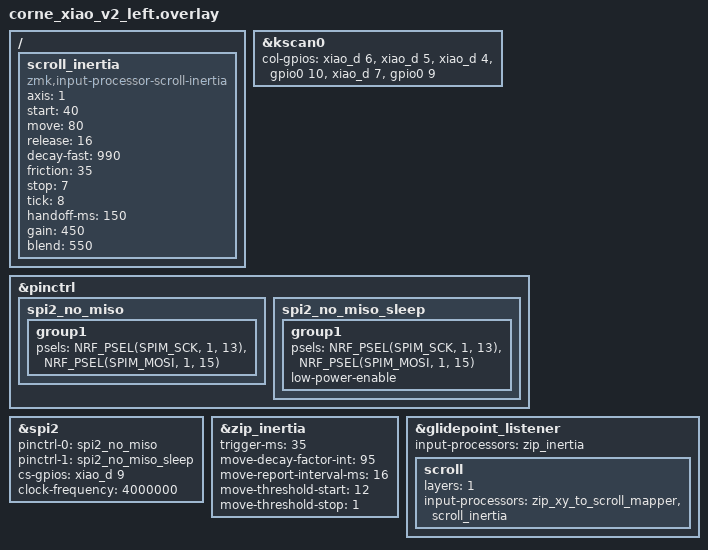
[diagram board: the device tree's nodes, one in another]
#include "corne_xiao_v2.dtsi"
#include <dt-bindings/zmk/input_transform.h>
#include <zmk-input-inertia/input/processor/input_inertia.dtsi>

&kscan0 {
    col-gpios
        = <&xiao_d 6 GPIO_ACTIVE_HIGH>
        , <&xiao_d 5 GPIO_ACTIVE_HIGH>
        , <&xiao_d 4 GPIO_ACTIVE_HIGH>
        , <&gpio0 10 GPIO_ACTIVE_HIGH>
        , <&xiao_d 7 GPIO_ACTIVE_HIGH>
        , <&gpio0  9 GPIO_ACTIVE_HIGH>
        ;
};

&pinctrl {
    spi2_no_miso: spi2_no_miso {
        group1 {
            psels = <NRF_PSEL(SPIM_SCK, 1, 13)>,
                    <NRF_PSEL(SPIM_MOSI, 1, 15)>;
        };
    };
    spi2_no_miso_sleep: spi2_no_miso_sleep {
        group1 {
            psels = <NRF_PSEL(SPIM_SCK, 1, 13)>,
                    <NRF_PSEL(SPIM_MOSI, 1, 15)>;
            low-power-enable;
        };
    };
};

nice_view_spi: &spi2 {
    status = "okay";
    pinctrl-0 = <&spi2_no_miso>;
    pinctrl-1 = <&spi2_no_miso_sleep>;
    pinctrl-names = "default", "sleep";
    cs-gpios = <&xiao_d 9 GPIO_ACTIVE_HIGH>;
    clock-frequency = <4000000>;
};

/ {
    scroll_inertia: scroll_inertia {
        compatible = "zmk,input-processor-scroll-inertia";
        #input-processor-cells = <0>;

        axis      = <1>;
        start     = <40>;
        move      = <80>;
        release   = <16>;
        decay-fast = <990>;
        friction  = <35>;
        stop      = <7>;
        tick      = <8>;
        handoff-ms = <150>;
        gain      = <450>;
        blend     = <550>;
    };
};

&zip_inertia {
    trigger-ms = <35>;

    move-decay-factor-int = <95>;
    move-report-interval-ms = <16>;
    move-threshold-start = <12>;
    move-threshold-stop = <1>;
};

&glidepoint_listener {
    status = "okay";
    input-processors = <&zip_inertia>;

    scroll {
        layers = <1>;
        input-processors = <&zip_xy_to_scroll_mapper>,
                           <&scroll_inertia>;
    };
};

// &left_encoder {
//     status = "okay";
// };
